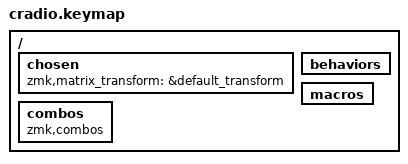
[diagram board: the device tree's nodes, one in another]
/*
 * Copyright (c) 2021 Darryl deHaan
 *
 * SPDX-License-Identifier: MIT
 */

/* #include "boards/arm/corneish_zen/corneish_zen_flash0.dtsi" // override &flash0 settings */

#include <behaviors.dtsi>
#include <dt-bindings/zmk/keys.h>
#include <dt-bindings/zmk/bt.h>
#include <dt-bindings/zmk/outputs.h>
#include <behaviors/num_word.dtsi>      // urob's num_word module


/ {
  chosen {
    zmk,matrix_transform = &default_transform;
    //zmk,matrix_transform = &five_column_transform;
  };
};

#include "moutis/moutis_config.dtsi"    // my add-on feature defs

#include "keymaps/keynames_3x5_2.h"     // key name defs for this board topology
#include "layouts/hd/vb-config.h"       // HD alpha keymap, adapt, and combo definitions

/ {
/*
 * Behaviors
 */
    behaviors {

#include "moutis/moutis_behaviors.dtsi" // common behaviors (hold-taps, mod-morphs, lingers, adaptives)
#include HD_adapt_file                  // HDalpha/mnemonic based adaptives (most of them)

    };

/*
 * Macros
 */
    macros {
    
#include "moutis/moutis_macros.dtsi"    // common macros (superset)

    };

/*
 * Combos
 */
    combos {
        compatible = "zmk,combos";

#include "moutis/moutis_combos.dtsi"    // common/location based combos (cut/copy/paste, esc, app, etc.)
#include HD_combo_file                  // HD alpha/mnemonic based combos (h-digraphs, etc.)

    };
/*
 * Keymap (all layers w/references to all the above)
 */

#include "keymaps/keymap_3x5_2.dtsi"    // consolidated keymap

};
